# G32M3101 register map
File version: 1.0
CPU: CM0+ r0p1, little endian, MPU, no FPU, 2 interrupt priority bits
Registers are 32-bit, read-write, reset 0x0 unless marked. A register's access mark holds for its fields unless they carry their own. Offsets are from the block's base; [hi:lo] are bit positions; {n}, {i} and the like mark numbered series; 'fields as' and 'values as' point back to an identical list.

## CRC — Cryptographic processor
Base 0x40020C00
0x00 DATA
  [31:0] DATA — As an input register: stores new data for the CRC calculator when writing; As an output register: returns the result of the CRC calculation when reading.
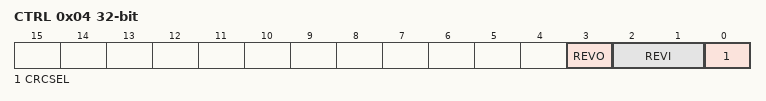
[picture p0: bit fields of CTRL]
0x04 CTRL — Control Register
  [3] REVO — Output data reverse
  [2:1] REVI — Input data reverse
  [0] CRCSEL — CRC selection
0x08 INITVAL — Initial value data register
  [31:0] VALUE — Initial CRC value

## COMP — Comparator
Base 0x40006000
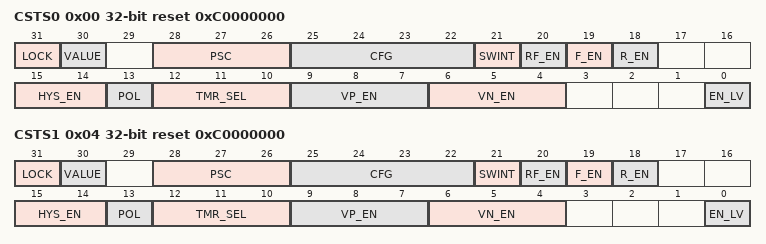
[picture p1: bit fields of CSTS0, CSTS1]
0x00 CSTS0 access per field reset 0xC0000000 — Control Register 0
  [31] LOCK rw
  [30] VALUE ro — Comparator outputs the level value before polarity selector and shielding.
  [28:26] PSC rw — Digital filter clock division
  [25:22] CFG rw — Number of clock cycles configured for digital filtering and frequency division
  [21] SWINT rw — Software Interruption
  [20] RF_EN rw — Comparator x enables interrupt on both rising and falling edges
  [19] F_EN rw — Comparator x enables interrupt on falling edges
  [18] R_EN rw — Comparator x enables interrupt on rising edges
  [15:14] HYS_EN rw — Comparator hysteresis enabled
  [13] POL rw — The output polarity of comparator.
  [12:10] TMR_SEL rw — Timer Select
  [9:7] VP_EN rw — Comparator positive input voltage selection
  [6:4] VN_EN rw — Comparator negative input voltage selection
  [0] EN_LV rw — Comparator enable
0x04 CSTS1 access per field reset 0xC0000000 — Control Register 1
  fields as CSTS0
0x08 STS0 — Status register 0
  [0] STS — interrupt flag
0x0C STS1 — Status Register 1
  [0] STS — interrupt flag

## WWDT — Window watchdog
Base 0x40007000
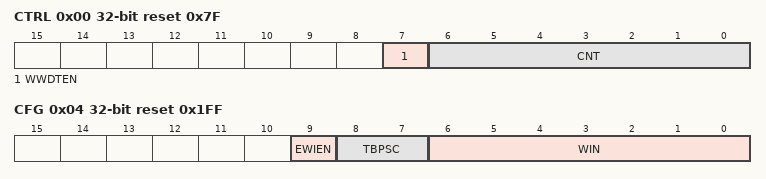
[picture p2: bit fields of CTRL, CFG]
0x00 CTRL reset 0x7F — Control register
  [7] WWDTEN — Activation bit
  [6:0] CNT — 7-bit counter (MSB to LSB)
0x04 CFG reset 0x1FF — Configuration register
  [9] EWIEN — Early wakeup interrupt
  [8:7] TBPSC — Timer Base Prescaler Factor Configure
  [6:0] WIN — 7-bit window value
0x08 STS — Status register
  [0] EWIFLG — Early wakeup interrupt flag

## IWDT — Independent watchdog
Base 0x40008000
0x00 KEY wo
  [15:0] KEY — Key value (write only, read 0000h)
0x04 PSC reset 0x7 — Prescaler register
  [2:0] PSC — Prescaler divider
0x08 CNTRLD reset 0xFFF — Reload register
  [11:0] CNTRLD — Watchdog counter reload value
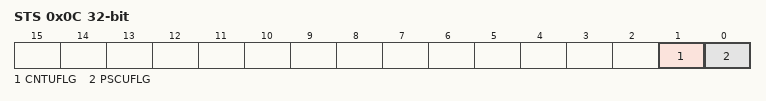
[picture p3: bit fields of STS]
0x0C STS ro — Status register
  [1] CNTUFLG — Watchdog prescaler value update
  [0] PSCUFLG — Watchdog counter reload value update

## DMA — DMA controller
Base 0x40020000
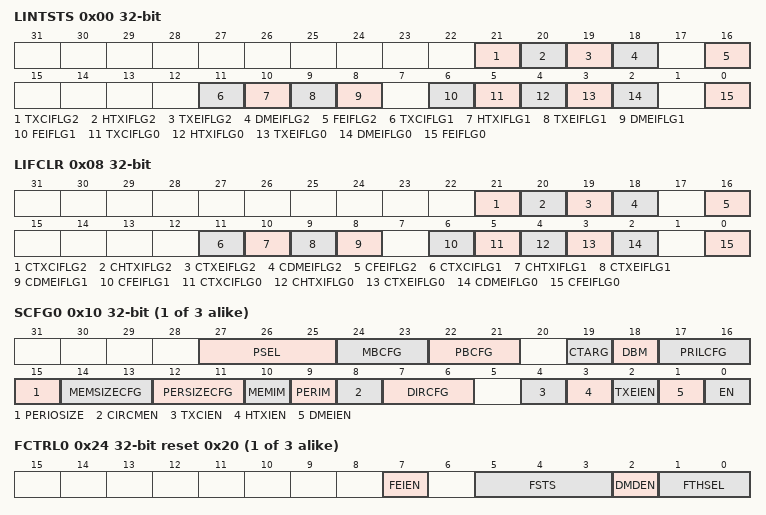
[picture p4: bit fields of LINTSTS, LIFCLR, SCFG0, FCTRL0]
0x00 LINTSTS ro
  [21] TXCIFLG2 — Stream 2 transfer complete interrupt flag
  [20] HTXIFLG2 — Stream 2 half transfer interrupt flag
  [19] TXEIFLG2 — Stream 2 transfer error interrupt flag
  [18] DMEIFLG2 — Stream 2 direct mode error interrupt flag
  [16] FEIFLG2 — Stream 2 FIFO error interrupt flag
  [11] TXCIFLG1 — Stream 1 transfer complete interrupt flag
  [10] HTXIFLG1 — Stream 1 half transfer interrupt flag
  [9] TXEIFLG1 — Stream 1 transfer error interrupt flag
  [8] DMEIFLG1 — Stream 1 direct mode error interrupt flag
  [6] FEIFLG1 — Stream 1 FIFO error interrupt flag
  [5] TXCIFLG0 — Stream 0 transfer complete interrupt flag
  [4] HTXIFLG0 — Stream 0 half transfer interrupt flag
  [3] TXEIFLG0 — Stream 0 transfer error interrupt flag
  [2] DMEIFLG0 — Stream 0 direct mode error interrupt flag
  [0] FEIFLG0 — Stream 0 FIFO error interrupt flag
0x08 LIFCLR wo
  [21] CTXCIFLG2 — Stream 2 clear transfer complete interrupt flag
  [20] CHTXIFLG2 — Stream 2 clear half transfer interrupt flag
  [19] CTXEIFLG2 — Stream 2 clear transfer error interrupt flag
  [18] CDMEIFLG2 — Stream 2 clear direct mode error interrupt flag
  [16] CFEIFLG2 — Stream 2 clear FIFO error interrupt flag
  [11] CTXCIFLG1 — Stream 1 clear transfer complete interrupt flag
  [10] CHTXIFLG1 — Stream 1 clear half transfer interrupt flag
  [9] CTXEIFLG1 — Stream 1 clear transfer error interrupt flag
  [8] CDMEIFLG1 — Stream 1 clear direct mode error interrupt flag
  [6] CFEIFLG1 — Stream 1 clear FIFO error interrupt flag
  [5] CTXCIFLG0 — Stream 0 clear transfer complete interrupt flag
  [4] CHTXIFLG0 — Stream 0 clear half transfer interrupt flag
  [3] CTXEIFLG0 — Stream 0 clear transfer error interrupt flag
  [2] CDMEIFLG0 — Stream 0 clear direct mode error interrupt flag
  [0] CFEIFLG0 — Stream 0 clear FIFO error interrupt flag
{0x10+0x18*i} SCFG{i} (i=0..2)
  [27:25] PSEL — Peripheral selection
  [24:23] MBCFG — Memory burst transfer configuration
  [22:21] PBCFG — Peripheral burst transfer configuration
  [19] CTARG — Current target (only in double buffer mode)
  [18] DBM — Double buffer mode
  [17:16] PRILCFG — Priority level
  [15] PERIOSIZE — Peripheral increment offset size
  [14:13] MEMSIZECFG — Memory data size
  [12:11] PERSIZECFG — Peripheral data size
  [10] MEMIM — Memory increment mode
  [9] PERIM — Peripheral increment mode
  [8] CIRCMEN — Circular mode
  [7:6] DIRCFG — Data transfer direction
  [4] TXCIEN — Transfer complete interrupt enable
  [3] HTXIEN — Half transfer interrupt enable
  [2] TXEIEN — Transfer error interrupt enable
  [1] DMEIEN — Direct mode error interrupt enable
  [0] EN — Stream enable / flag stream ready when read low
{0x14+0x18*i} NDATA{i} (i=0..2)
  [15:0] NDATA — Number of data items to transfer
{0x18+0x18*i} PADDR{i} (i=0..2)
  [31:0] PADDR — Peripheral address
{0x1C+0x18*i} M0ADDR{i} (i=0..2)
  [31:0] M0ADDR — Memory 0 address
{0x20+0x18*i} M1ADDR{i} (i=0..2)
  [31:0] M1ADDR — Memory 1 address (used in case of Double buffer mode)
{0x24+0x18*i} FCTRL{i} access per field reset 0x20 (i=0..2)
  [7] FEIEN rw — FIFO error interrupt enable
  [5:3] FSTS ro — FIFO status
  [2] DMDEN rw — Direct mode disable
  [1:0] FTHSEL rw — FIFO threshold selection
